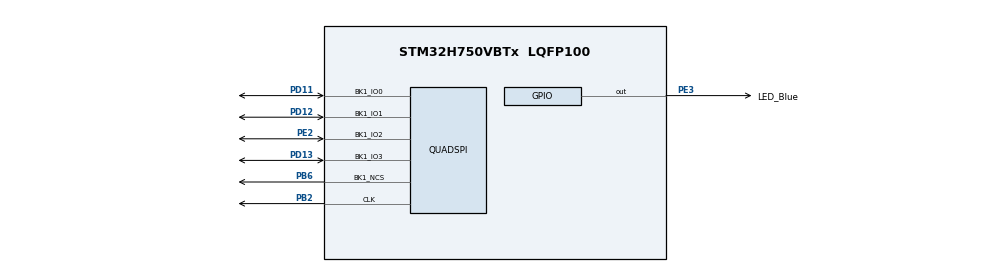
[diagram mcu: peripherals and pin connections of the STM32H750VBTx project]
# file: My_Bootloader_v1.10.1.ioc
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CORTEX_M7.BaseAddress-Cortex_Memory_Protection_Unit_Region0_Settings=0x90000000
CORTEX_M7.DisableExec-Cortex_Memory_Protection_Unit_Region0_Settings=MPU_INSTRUCTION_ACCESS_DISABLE
CORTEX_M7.Enable-Cortex_Memory_Protection_Unit_Region0_Settings=MPU_REGION_ENABLE
CORTEX_M7.IsShareable-Cortex_Memory_Protection_Unit_Region0_Settings=MPU_ACCESS_SHAREABLE
CORTEX_M7.MPU_Control=MPU_PRIVILEGED_DEFAULT
CORTEX_M7.Size-Cortex_Memory_Protection_Unit_Region0_Settings=MPU_REGION_SIZE_8MB
Mcu.Family=STM32H7
Mcu.Name=STM32H750VBTx
Mcu.Package=LQFP100
NVIC.PriorityGroup=NVIC_PRIORITYGROUP_4
NVIC.QUADSPI_IRQn=true\:0\:0\:false\:false\:true\:true\:true\:true
PA13\ (JTMS/SWDIO).Mode=Serial_Wire
PA13\ (JTMS/SWDIO).Signal=DEBUG_JTMS-SWDIO
PA14\ (JTCK/SWCLK).Mode=Serial_Wire
PA14\ (JTCK/SWCLK).Signal=DEBUG_JTCK-SWCLK
PB2.GPIO_Speed=GPIO_SPEED_FREQ_VERY_HIGH
PB2.Mode=Single Bank 1
PB2.Signal=QUADSPI_CLK
PB6.GPIO_Speed=GPIO_SPEED_FREQ_VERY_HIGH
PB6.Mode=Single Bank 1
PB6.Signal=QUADSPI_BK1_NCS
PC14-OSC32_IN\ (OSC32_IN).Mode=LSE-External-Oscillator
PC14-OSC32_IN\ (OSC32_IN).Signal=RCC_OSC32_IN
PC15-OSC32_OUT\ (OSC32_OUT).Mode=LSE-External-Oscillator
PC15-OSC32_OUT\ (OSC32_OUT).Signal=RCC_OSC32_OUT
PD11.GPIO_Speed=GPIO_SPEED_FREQ_VERY_HIGH
PD11.Mode=Single Bank 1
PD11.Signal=QUADSPI_BK1_IO0
PD12.GPIO_Speed=GPIO_SPEED_FREQ_VERY_HIGH
PD12.Mode=Single Bank 1
PD12.Signal=QUADSPI_BK1_IO1
PD13.GPIO_Speed=GPIO_SPEED_FREQ_VERY_HIGH
PD13.Mode=Single Bank 1
PD13.Signal=QUADSPI_BK1_IO3
PE2.GPIO_Speed=GPIO_SPEED_FREQ_VERY_HIGH
PE2.Mode=Single Bank 1
PE2.Signal=QUADSPI_BK1_IO2
PE3.GPIO_Label=LED_Blue
PE3.Signal=GPIO_Output
PH0-OSC_IN\ (PH0).Mode=HSE-External-Oscillator
PH0-OSC_IN\ (PH0).Signal=RCC_OSC_IN
PH1-OSC_OUT\ (PH1).Mode=HSE-External-Oscillator
PH1-OSC_OUT\ (PH1).Signal=RCC_OSC_OUT
ProjectManager.HeapSize=0x200
ProjectManager.StackSize=0x400
ProjectManager.TargetToolchain=STM32CubeIDE
QUADSPI.ChipSelectHighTime=QSPI_CS_HIGH_TIME_6_CYCLE
QUADSPI.ClockPrescaler=1
QUADSPI.FlashSize=22
RCC.ADCFreq_Value=50390625
RCC.APB1Freq_Value=100000000
RCC.APB2Freq_Value=100000000
RCC.APB3Freq_Value=100000000
RCC.APB4Freq_Value=100000000
RCC.CortexFreq_Value=200000000
RCC.DIVM1=2
RCC.DIVN1=32
RCC.HCLKFreq_Value=100000000
RCC.HPRE=RCC_HCLK_DIV2
RCC.PLLSourceVirtual=RCC_PLLSOURCE_HSE
RCC.SYSCLKFreq_VALUE=200000000
RCC.SYSCLKSource=RCC_SYSCLKSOURCE_PLLCLK
RCC.USART234578CLockSelection=RCC_USART234578CLKSOURCE_CSI
RCC.USBFreq_Value=200000000
board=custom

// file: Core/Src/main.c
/* USER CODE BEGIN Header */
/**
  ******************************************************************************
  * @file           : main.c
  * @brief          : Main program body
  ******************************************************************************
  * @attention
  *
  * Copyright (c) 2022 STMicroelectronics.
  * All rights reserved.
  *
  * This software is licensed under terms that can be found in the LICENSE file
  * in the root directory of this software component.
  * If no LICENSE file comes with this software, it is provided AS-IS.
  *
  ******************************************************************************
  */
/* USER CODE END Header */
#include "main.h"
#include "quadspi.h"
#include "gpio.h"

/* USER CODE BEGIN PV */
typedef void (*pFunction)(void);
pFunction JumpToApplication;
/* USER CODE END PV */

void SystemClock_Config(void);
static void MPU_Config(void);

int main(void)
{

  /* MPU Configuration--------------------------------------------------------*/
  MPU_Config();

  /* MCU Configuration--------------------------------------------------------*/

  /* Reset of all peripherals, Initializes the Flash interface and the Systick. */
  HAL_Init();

  /* Configure the system clock */
  SystemClock_Config();

  /* Initialize all configured peripherals */
  MX_GPIO_Init();
  MX_QUADSPI_Init();
  /* USER CODE BEGIN 2 */
  if (QSPI_W25Qxx_Init() != QSPI_W25Qxx_OK){  //重新初始化QSPI-flash
  	  Error_Handler();
    }
  QSPI_W25Qxx_MemoryMappedMode();     //Установите QSPI как режим отображения памяти
  HAL_MPU_Disable();                  //关闭mpu

  SysTick->CTRL = 0;        // 关闭SysTick
  SysTick->LOAD = 0;        // 清零重载值
  SysTick->VAL = 0;            // 清零计数值
  /* Initialize user application's Stack Pointer */
  JumpToApplication = (pFunction) (*(__IO uint32_t *) (W25Qxx_Mem_Addr + 4));    // 设置起始地址
  __set_MSP(*(__IO uint32_t *) W25Qxx_Mem_Addr);    // 设置主堆栈指针
  /* In the RTOS project, this statement is very important, set to privileged mode, use MSP pointer */
  __set_CONTROL(0); // для FreeRTOS application
  /* Jump to the system BootLoader */
  JumpToApplication();            // 执行跳转
  /* USER CODE END 2 */

  /* Infinite loop */
  while (1)
  {

  }
}

void SystemClock_Config(void)
{
  RCC_OscInitTypeDef RCC_OscInitStruct = {0};
  RCC_ClkInitTypeDef RCC_ClkInitStruct = {0};

  /** Supply configuration update enable
  */
  HAL_PWREx_ConfigSupply(PWR_LDO_SUPPLY);

  /** Configure the main internal regulator output voltage
  */
  __HAL_PWR_VOLTAGESCALING_CONFIG(PWR_REGULATOR_VOLTAGE_SCALE3);

  while(!__HAL_PWR_GET_FLAG(PWR_FLAG_VOSRDY)) {}

  /** Initializes the RCC Oscillators according to the specified parameters
  * in the RCC_OscInitTypeDef structure.
  */
  RCC_OscInitStruct.OscillatorType = RCC_OSCILLATORTYPE_HSE;
  RCC_OscInitStruct.HSEState = RCC_HSE_ON;
  RCC_OscInitStruct.PLL.PLLState = RCC_PLL_ON;
  RCC_OscInitStruct.PLL.PLLSource = RCC_PLLSOURCE_HSE;
  RCC_OscInitStruct.PLL.PLLM = 2;
  RCC_OscInitStruct.PLL.PLLN = 32;
  RCC_OscInitStruct.PLL.PLLP = 2;
  RCC_OscInitStruct.PLL.PLLQ = 2;
  RCC_OscInitStruct.PLL.PLLR = 2;
  RCC_OscInitStruct.PLL.PLLRGE = RCC_PLL1VCIRANGE_3;
  RCC_OscInitStruct.PLL.PLLVCOSEL = RCC_PLL1VCOWIDE;
  RCC_OscInitStruct.PLL.PLLFRACN = 0;
  if (HAL_RCC_OscConfig(&RCC_OscInitStruct) != HAL_OK)
  {
    Error_Handler();
  }

  /** Initializes the CPU, AHB and APB buses clocks
  */
  RCC_ClkInitStruct.ClockType = RCC_CLOCKTYPE_HCLK|RCC_CLOCKTYPE_SYSCLK
                              |RCC_CLOCKTYPE_PCLK1|RCC_CLOCKTYPE_PCLK2
                              |RCC_CLOCKTYPE_D3PCLK1|RCC_CLOCKTYPE_D1PCLK1;
  RCC_ClkInitStruct.SYSCLKSource = RCC_SYSCLKSOURCE_PLLCLK;
  RCC_ClkInitStruct.SYSCLKDivider = RCC_SYSCLK_DIV1;
  RCC_ClkInitStruct.AHBCLKDivider = RCC_HCLK_DIV2;
  RCC_ClkInitStruct.APB3CLKDivider = RCC_APB3_DIV1;
  RCC_ClkInitStruct.APB1CLKDivider = RCC_APB1_DIV1;
  RCC_ClkInitStruct.APB2CLKDivider = RCC_APB2_DIV1;
  RCC_ClkInitStruct.APB4CLKDivider = RCC_APB4_DIV1;

  if (HAL_RCC_ClockConfig(&RCC_ClkInitStruct, FLASH_LATENCY_2) != HAL_OK)
  {
    Error_Handler();
  }
}

/* MPU Configuration */

void MPU_Config(void)
{
  MPU_Region_InitTypeDef MPU_InitStruct = {0};

  /* Disables the MPU */
  HAL_MPU_Disable();

  /** Initializes and configures the Region and the memory to be protected
  */
  MPU_InitStruct.Enable = MPU_REGION_ENABLE;
  MPU_InitStruct.Number = MPU_REGION_NUMBER0;
  MPU_InitStruct.BaseAddress = 0x90000000;
  MPU_InitStruct.Size = MPU_REGION_SIZE_8MB;
  MPU_InitStruct.SubRegionDisable = 0x0;
  MPU_InitStruct.TypeExtField = MPU_TEX_LEVEL0;
  MPU_InitStruct.AccessPermission = MPU_REGION_NO_ACCESS;
  MPU_InitStruct.DisableExec = MPU_INSTRUCTION_ACCESS_DISABLE;
  MPU_InitStruct.IsShareable = MPU_ACCESS_SHAREABLE;
  MPU_InitStruct.IsCacheable = MPU_ACCESS_NOT_CACHEABLE;
  MPU_InitStruct.IsBufferable = MPU_ACCESS_NOT_BUFFERABLE;

  HAL_MPU_ConfigRegion(&MPU_InitStruct);
  /* Enables the MPU */
  HAL_MPU_Enable(MPU_PRIVILEGED_DEFAULT);

}

void Error_Handler(void)
{
  __disable_irq();
  while (1)
  {
  }
}
